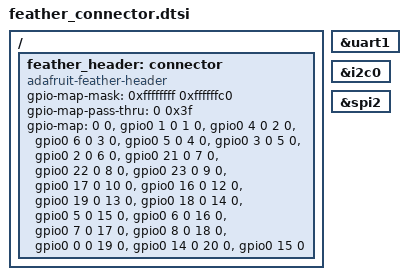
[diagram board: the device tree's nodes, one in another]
/*
 * Copyright (c) 2026 Tim Boldt
 *
 * SPDX-License-Identifier: Apache-2.0
 *
 * Adafruit Feather header nexus for the ESP32-C6 Feather.
 *
 * Pin map from Adafruit's CircuitPython board definition
 * (ports/espressif/boards/adafruit_feather_esp32c6_4mbflash_nopsram/pins.c),
 * cross-checked against https://learn.adafruit.com/adafruit-esp32-c6-feather/pinouts
 * and, for D5/D6/D9/D10, against the working TFT FeatherWing:
 *   A0 = IO1   A1 = IO4   A2 = IO6   A3 = IO5   A4 = IO3   A5 = IO2
 *   D5 = IO5   D6 = IO6   (shared with A3 / A2)
 *   D9 = IO7   D10 = IO8  D11 = IO0  D12 = IO14  D13 = IO15 (red LED)
 *   SCK = IO21  MOSI = IO22  MISO = IO23
 *   RX  = IO17  TX   = IO16
 *   SDA = IO19  SCL  = IO18
 *   IO9 is the Boot button + on-board NeoPixel (and a strapping pin).
 *   D4 is not broken out on this Feather.
 */

/ {
	feather_header: connector {
		compatible = "adafruit-feather-header";
		#gpio-cells = <2>;
		gpio-map-mask = <0xffffffff 0xffffffc0>;
		gpio-map-pass-thru = <0 0x3f>;
		gpio-map = <
			0 0 &gpio0 1 0		/* A0  */
			1 0 &gpio0 4 0		/* A1  */
			2 0 &gpio0 6 0		/* A2  */
			3 0 &gpio0 5 0		/* A3  */
			4 0 &gpio0 3 0		/* A4  */
			5 0 &gpio0 2 0		/* A5  */
			6 0 &gpio0 21 0		/* SCK  */
			7 0 &gpio0 22 0		/* MOSI */
			8 0 &gpio0 23 0		/* MISO */
			9 0 &gpio0 17 0		/* RX   */
			10 0 &gpio0 16 0	/* TX   */
			/* 11  D4: not broken out */
			12 0 &gpio0 19 0	/* SDA  */
			13 0 &gpio0 18 0	/* SCL  */
			14 0 &gpio0 5 0		/* D5  */
			15 0 &gpio0 6 0		/* D6  */
			16 0 &gpio0 7 0		/* D9  */
			17 0 &gpio0 8 0		/* D10 */
			18 0 &gpio0 0 0		/* D11 */
			19 0 &gpio0 14 0	/* D12 */
			20 0 &gpio0 15 0	/* D13 (red LED) */
		>;
	};
};

feather_serial: &uart1 {};

feather_i2c: &i2c0 {};

feather_spi: &spi2 {};
